# HC32K116 register map
File version: 1.0
CPU: CM0+ r0p1, little endian, no MPU, no FPU, 2 interrupt priority bits
Registers are 32-bit, read-write, reset 0x0 unless marked. A register's access mark holds for its fields unless they carry their own. Offsets are from the block's base; [hi:lo] are bit positions; {n}, {i} and the like mark numbered series.

## AOS
Base 0x40000C00
0x00 INTSFTTRG wo
  [0] STRG
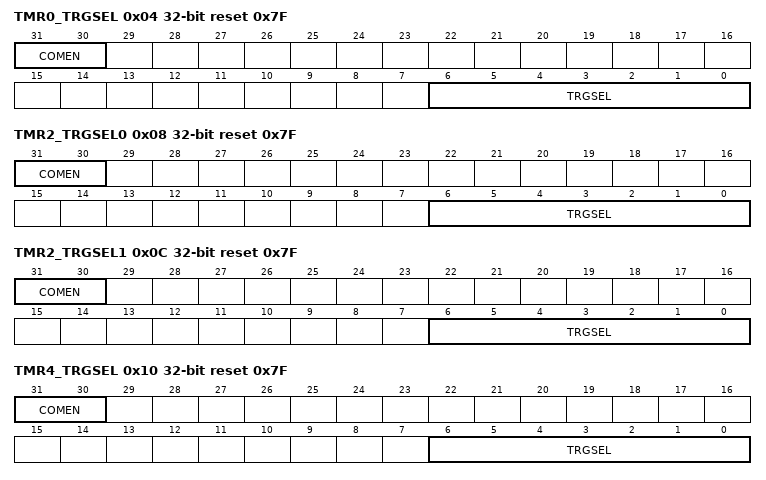
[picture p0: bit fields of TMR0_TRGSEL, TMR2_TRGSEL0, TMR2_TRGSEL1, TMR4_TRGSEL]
0x04 TMR0_TRGSEL reset 0x7F
  [31:30] COMEN, [6:0] TRGSEL
0x08 TMR2_TRGSEL0 reset 0x7F
  [31:30] COMEN, [6:0] TRGSEL
0x0C TMR2_TRGSEL1 reset 0x7F
  [31:30] COMEN, [6:0] TRGSEL
0x10 TMR4_TRGSEL reset 0x7F
  [31:30] COMEN, [6:0] TRGSEL
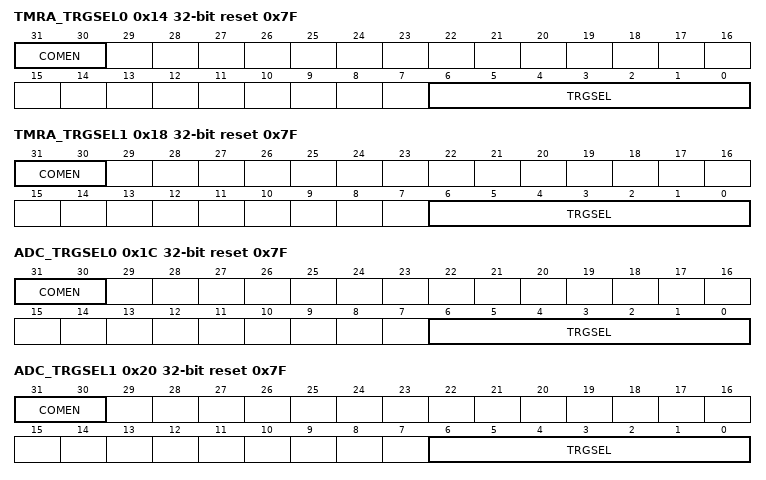
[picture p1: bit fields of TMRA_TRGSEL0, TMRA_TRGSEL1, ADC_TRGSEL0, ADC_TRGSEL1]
0x14 TMRA_TRGSEL0 reset 0x7F
  [31:30] COMEN, [6:0] TRGSEL
0x18 TMRA_TRGSEL1 reset 0x7F
  [31:30] COMEN, [6:0] TRGSEL
0x1C ADC_TRGSEL0 reset 0x7F
  [31:30] COMEN, [6:0] TRGSEL
0x20 ADC_TRGSEL1 reset 0x7F
  [31:30] COMEN, [6:0] TRGSEL
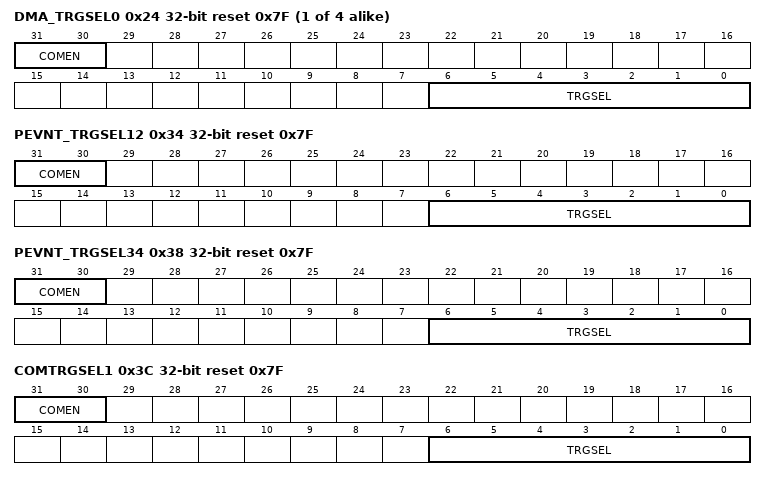
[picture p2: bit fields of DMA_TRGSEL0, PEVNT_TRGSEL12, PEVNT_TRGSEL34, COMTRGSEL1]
{0x24+4i} DMA_TRGSEL{i} reset 0x7F (i=0..3)
  [31:30] COMEN, [6:0] TRGSEL
0x34 PEVNT_TRGSEL12 reset 0x7F
  [31:30] COMEN, [6:0] TRGSEL
0x38 PEVNT_TRGSEL34 reset 0x7F
  [31:30] COMEN, [6:0] TRGSEL
0x3C COMTRGSEL1 reset 0x7F
  [31:30] COMEN, [6:0] TRGSEL
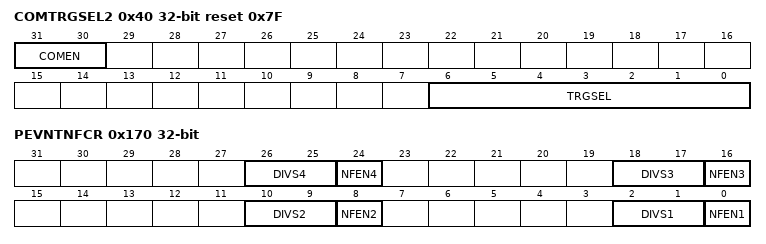
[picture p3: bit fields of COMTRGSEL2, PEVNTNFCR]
0x40 COMTRGSEL2 reset 0x7F
  [31:30] COMEN, [6:0] TRGSEL
{0xE4+0x1C*i} PEVNTDIRR{i} (i=1..4)
  [15:0] PDIR
{0xE8+0x1C*i} PEVNTIDR{i} ro (i=1..4)
  [15:0] PIN
{0xEC+0x1C*i} PEVNTODR{i} (i=1..4)
  [15:0] POUT
{0xF0+0x1C*i} PEVNTORR{i} (i=1..4)
  [15:0] POR
{0xF4+0x1C*i} PEVNTOSR{i} (i=1..4)
  [15:0] POS
{0xF8+0x1C*i} PEVNTRISR{i} (i=1..4)
  [15:0] RIS
{0xFC+0x1C*i} PEVNTFALR{i} (i=1..4)
  [15:0] FAL
0x170 PEVNTNFCR
  [8n-6:8n-7] DIVS{n} (n=1..4), [8n-8] NFEN{n} (n=1..4)

## CMP
Base 0x4000C800
0x00 MDR 8-bit
  [0] CENA
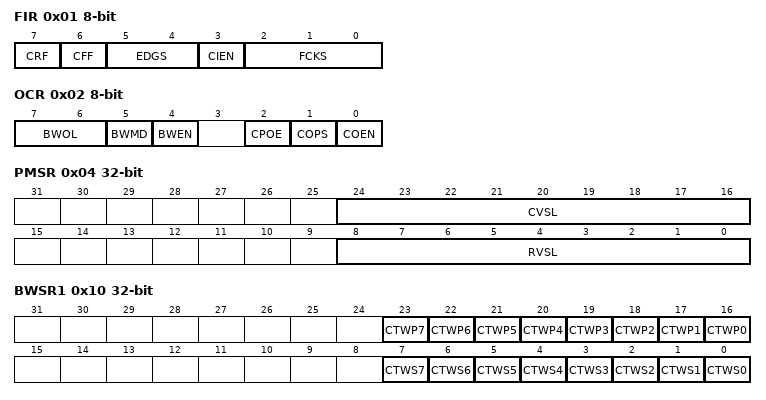
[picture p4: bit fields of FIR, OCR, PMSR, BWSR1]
0x01 FIR 8-bit
  [7] CRF, [6] CFF, [5:4] EDGS, [3] CIEN, [2:0] FCKS
0x02 OCR 8-bit
  [7:6] BWOL, [5] BWMD, [4] BWEN, [2] CPOE, [1] COPS, [0] COEN
0x03 OMR 8-bit ro
  [0] CMON
0x04 PMSR
  [24:16] CVSL, [8:0] RVSL
0x0C DADR 16-bit
  [7:0] DATA
0x0E DACR 16-bit
  [0] DAE
0x10 BWSR1
  [n+16] CTWP{n} (n=0..7), [n] CTWS{n} (n=0..7)
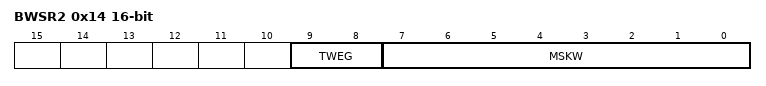
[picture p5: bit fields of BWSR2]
0x14 BWSR2 16-bit
  [9:8] TWEG, [7:0] MSKW

## CMU
Base 0x40014400
0x00 PERICKSEL 8-bit
  [2:0] PERICKSEL
0x04 XTALSTDSR 8-bit
  [0] XTALSTDF
0x08 SCKDIVR 8-bit
  [2:0] SCKDIV
0x0C CKSWR 8-bit
  [1:0] CKSW
0x10 XTALCR 8-bit reset 0x1
  [0] XTALSTP
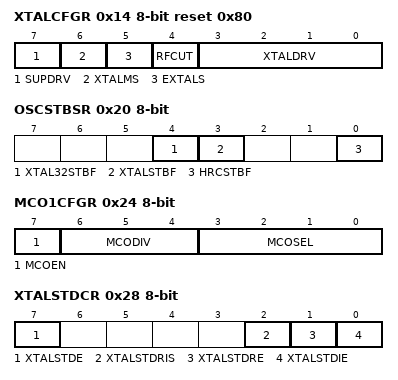
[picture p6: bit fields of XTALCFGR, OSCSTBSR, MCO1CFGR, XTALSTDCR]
0x14 XTALCFGR 8-bit reset 0x80
  [7] SUPDRV, [6] XTALMS, [5] EXTALS, [4] RFCUT, [3:0] XTALDRV
0x15 XTALSTBCR 8-bit
  [2:0] XTALSTB
0x18 HRCCR 8-bit
  [0] HRCSTP
0x20 OSCSTBSR 8-bit ro
  [4] XTAL32STBF, [3] XTALSTBF, [0] HRCSTBF
0x24 MCO1CFGR 8-bit
  [7] MCOEN, [6:4] MCODIV, [3:0] MCOSEL
0x28 XTALSTDCR 8-bit
  [7] XTALSTDE, [2] XTALSTDRIS, [1] XTALSTDRE, [0] XTALSTDIE
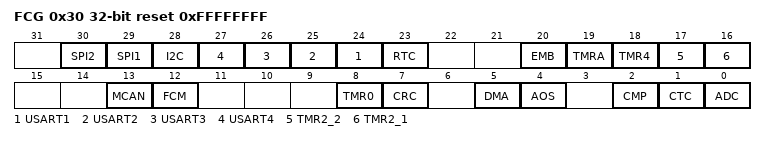
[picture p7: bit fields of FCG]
0x30 FCG reset 0xFFFFFFFF
  [30] SPI2, [29] SPI1, [28] I2C, [n+23] USART{n} (n=1..4), [23] RTC, [20] EMB, [19] TMRA, [18] TMR4, [17] TMR2_2, [16] TMR2_1, [13] MCAN, [12] FCM, [8] TMR0, [7] CRC, [5] DMA, [4] AOS, [2] CMP, [1] CTC, [0] ADC
0x34 XTAL32CR 8-bit reset 0x1
  [0] XTAL32STP
0x38 XTAL32CFGR 8-bit
  [0] XTAL32DRV
0x39 XTAL32NFR 8-bit
  [1:0] XTAL32NF
0x3C LRCCR 8-bit
  [0] LRCSTP
0x40 CANCKCFGR 8-bit
  [0] MCANCKS

## CRC
Base 0x40015400
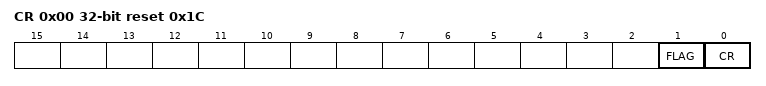
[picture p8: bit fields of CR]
0x00 CR reset 0x1C
  [1] FLAG ro, [0] CR
0x04 RESLT reset 0x7800
{0x80+4i} DAT{i} wo (i=0..31)

## CTC
Base 0x40000000
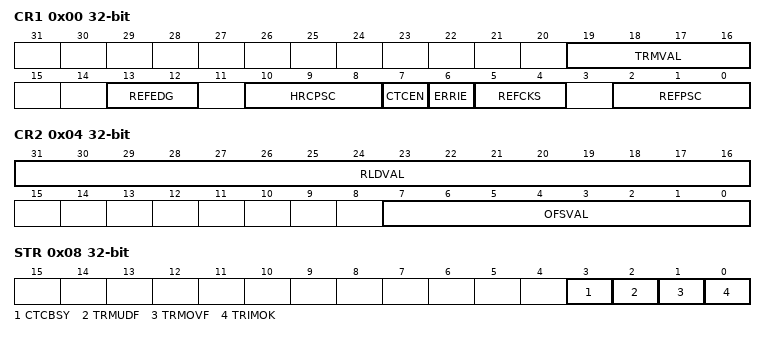
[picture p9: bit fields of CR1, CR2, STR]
0x00 CR1
  [19:16] TRMVAL, [13:12] REFEDG, [10:8] HRCPSC, [7] CTCEN, [6] ERRIE, [5:4] REFCKS, [2:0] REFPSC
0x04 CR2
  [31:16] RLDVAL, [7:0] OFSVAL
0x08 STR ro
  [3] CTCBSY, [2] TRMUDF, [1] TRMOVF, [0] TRIMOK
0x0C CNT 16-bit ro

## DBGC
Base 0x40015000
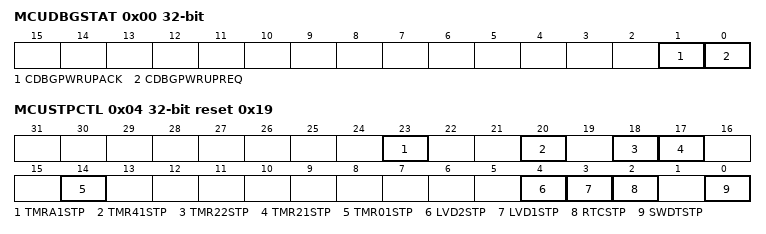
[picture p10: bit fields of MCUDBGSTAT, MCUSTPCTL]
0x00 MCUDBGSTAT
  [1] CDBGPWRUPACK, [0] CDBGPWRUPREQ
0x04 MCUSTPCTL reset 0x19
  [23] TMRA1STP, [20] TMR41STP, [18] TMR22STP, [17] TMR21STP, [14] TMR01STP, [4] LVD2STP, [3] LVD1STP, [2] RTCSTP, [0] SWDTSTP

## DBGC_T
Base 0xE0042000
{0x0+4i} AUTHID{i} (i=0..2)
0x0C CHIPID ro reset 0x58480118
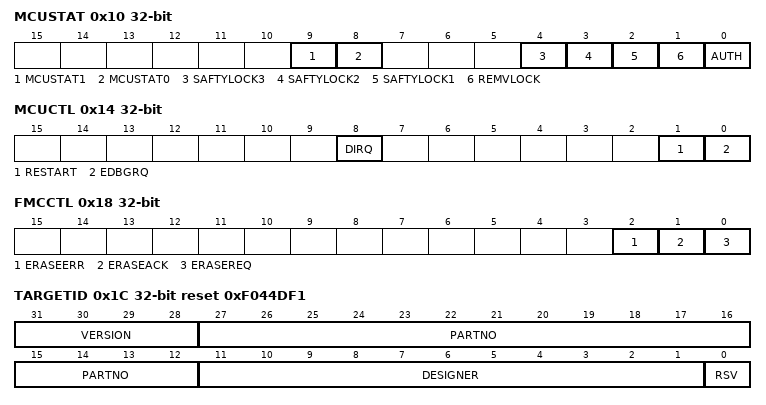
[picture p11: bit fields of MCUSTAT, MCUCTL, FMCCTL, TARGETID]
0x10 MCUSTAT
  [9] MCUSTAT1, [8] MCUSTAT0, [4] SAFTYLOCK3, [3] SAFTYLOCK2, [2] SAFTYLOCK1, [1] REMVLOCK, [0] AUTH
0x14 MCUCTL
  [8] DIRQ, [1] RESTART, [0] EDBGRQ
0x18 FMCCTL
  [2] ERASEERR, [1] ERASEACK, [0] ERASEREQ
0x1C TARGETID ro reset 0xF044DF1
  [31:28] VERSION, [27:12] PARTNO, [11:1] DESIGNER, [0] RSV
